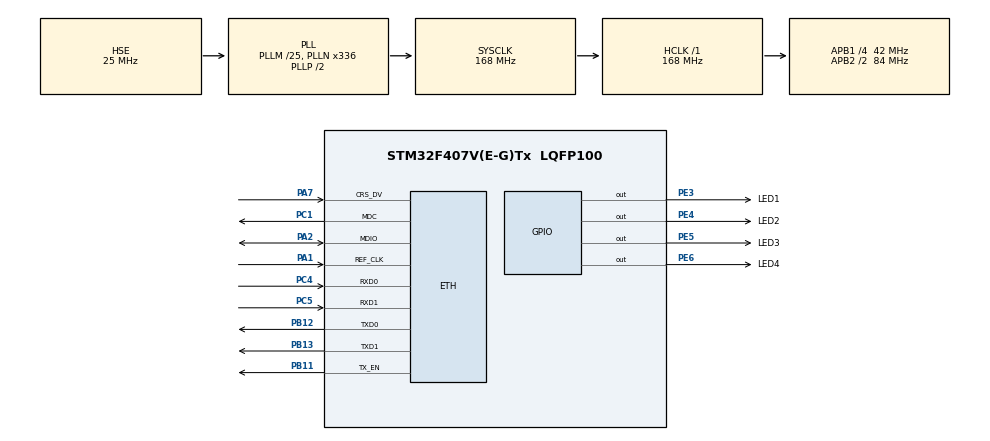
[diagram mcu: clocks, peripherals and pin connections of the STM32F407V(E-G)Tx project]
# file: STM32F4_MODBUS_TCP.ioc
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ETH.MediaInterface=ETH_MEDIA_INTERFACE_RMII
LWIP.GATEWAY_ADDRESS=017.091.001.002
LWIP.IP_ADDRESS=017.091.023.196
LWIP.LWIP_DHCP=0
LWIP.LWIP_UDP=1
LWIP.MEMP_NUM_TCP_PCB=3
LWIP.MEMP_NUM_UDP_PCB=3
LWIP.NETMASK_ADDRESS=255.255.224.000
LWIP.TCP_MSS=1460
LWIP.Version=v2.0.0_Cube
Mcu.Family=STM32F4
Mcu.Name=STM32F407V(E-G)Tx
Mcu.Package=LQFP100
NVIC.PriorityGroup=NVIC_PRIORITYGROUP_4
PA1.Mode=RMII
PA1.Signal=ETH_REF_CLK
PA13.Mode=JTAG_5_pins
PA13.Signal=SYS_JTMS-SWDIO
PA14.Mode=JTAG_5_pins
PA14.Signal=SYS_JTCK-SWCLK
PA15.Mode=JTAG_5_pins
PA15.Signal=SYS_JTDI
PA2.Mode=RMII
PA2.Signal=ETH_MDIO
PA7.Mode=RMII
PA7.Signal=ETH_CRS_DV
PB11.Mode=RMII
PB11.Signal=ETH_TX_EN
PB12.Mode=RMII
PB12.Signal=ETH_TXD0
PB13.Mode=RMII
PB13.Signal=ETH_TXD1
PB3.Mode=JTAG_5_pins
PB3.Signal=SYS_JTDO-SWO
PB4.Mode=JTAG_5_pins
PB4.Signal=SYS_JTRST
PC1.Mode=RMII
PC1.Signal=ETH_MDC
PC14-OSC32_IN.Mode=LSE-External-Oscillator
PC14-OSC32_IN.Signal=RCC_OSC32_IN
PC15-OSC32_OUT.Mode=LSE-External-Oscillator
PC15-OSC32_OUT.Signal=RCC_OSC32_OUT
PC4.Mode=RMII
PC4.Signal=ETH_RXD0
PC5.Mode=RMII
PC5.Signal=ETH_RXD1
PE3.GPIO_Label=LED1
PE3.Signal=GPIO_Output
PE4.GPIO_Label=LED2
PE4.Signal=GPIO_Output
PE5.GPIO_Label=LED3
PE5.Signal=GPIO_Output
PE6.GPIO_Label=LED4
PE6.Signal=GPIO_Output
PH0-OSC_IN.Mode=HSE-External-Oscillator
PH0-OSC_IN.Signal=RCC_OSC_IN
PH1-OSC_OUT.Mode=HSE-External-Oscillator
PH1-OSC_OUT.Signal=RCC_OSC_OUT
ProjectManager.HeapSize=0x200
ProjectManager.StackSize=0x400
ProjectManager.TargetToolchain=EWARM
RCC.48MHZClocksFreq_Value=84000000
RCC.AHBFreq_Value=168000000
RCC.APB1CLKDivider=RCC_HCLK_DIV4
RCC.APB1Freq_Value=42000000
RCC.APB1TimFreq_Value=84000000
RCC.APB2CLKDivider=RCC_HCLK_DIV2
RCC.APB2Freq_Value=84000000
RCC.APB2TimFreq_Value=168000000
RCC.CortexFreq_Value=168000000
RCC.HCLKFreq_Value=168000000
RCC.HSE_VALUE=25000000
RCC.HSI_VALUE=16000000
RCC.PLLM=25
RCC.PLLN=336
RCC.PLLSourceVirtual=RCC_PLLSOURCE_HSE
RCC.SYSCLKFreq_VALUE=168000000
RCC.SYSCLKSource=RCC_SYSCLKSOURCE_PLLCLK
RCC.VCOOutputFreq_Value=336000000
VP_LWIP_VS_Enabled.Mode=Enabled
VP_TIM7_VS_ClockSourceINT.Mode=Enable_Timer
board=STM32F4_MODBUS_TCP

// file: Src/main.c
/**
  ******************************************************************************
  * File Name          : main.c
  * Description        : Main program body
  ******************************************************************************
  * This notice applies to any and all portions of this file
  * that are not between comment pairs USER CODE BEGIN and
  * USER CODE END. Other portions of this file, whether
  * inserted by the user or by software development tools
  * are owned by their respective copyright owners.
  *
  * Copyright (c) 2017 STMicroelectronics International N.V.
  * All rights reserved.
  *
  * Redistribution and use in source and binary forms, with or without
  * modification, are permitted, provided that the following conditions are met:
  *
  * 1. Redistribution of source code must retain the above copyright notice,
  *    this list of conditions and the following disclaimer.
  * 2. Redistributions in binary form must reproduce the above copyright notice,
  *    this list of conditions and the following disclaimer in the documentation
  *    and/or other materials provided with the distribution.
  * 3. Neither the name of STMicroelectronics nor the names of other
  *    contributors to this software may be used to endorse or promote products
  *    derived from this software without specific written permission.
  * 4. This software, including modifications and/or derivative works of this
  *    software, must execute solely and exclusively on microcontroller or
  *    microprocessor devices manufactured by or for STMicroelectronics.
  * 5. Redistribution and use of this software other than as permitted under
  *    this license is void and will automatically terminate your rights under
  *    this license.
  *
  * THIS SOFTWARE IS PROVIDED BY STMICROELECTRONICS AND CONTRIBUTORS "AS IS"
  * AND ANY EXPRESS, IMPLIED OR STATUTORY WARRANTIES, INCLUDING, BUT NOT
  * LIMITED TO, THE IMPLIED WARRANTIES OF MERCHANTABILITY, FITNESS FOR A
  * PARTICULAR PURPOSE AND NON-INFRINGEMENT OF THIRD PARTY INTELLECTUAL PROPERTY
  * RIGHTS ARE DISCLAIMED TO THE FULLEST EXTENT PERMITTED BY LAW. IN NO EVENT
  * SHALL STMICROELECTRONICS OR CONTRIBUTORS BE LIABLE FOR ANY DIRECT, INDIRECT,
  * INCIDENTAL, SPECIAL, EXEMPLARY, OR CONSEQUENTIAL DAMAGES (INCLUDING, BUT NOT
  * LIMITED TO, PROCUREMENT OF SUBSTITUTE GOODS OR SERVICES; LOSS OF USE, DATA,
  * OR PROFITS; OR BUSINESS INTERRUPTION) HOWEVER CAUSED AND ON ANY THEORY OF
  * LIABILITY, WHETHER IN CONTRACT, STRICT LIABILITY, OR TORT (INCLUDING
  * NEGLIGENCE OR OTHERWISE) ARISING IN ANY WAY OUT OF THE USE OF THIS SOFTWARE,
  * EVEN IF ADVISED OF THE POSSIBILITY OF SUCH DAMAGE.
  *
  ******************************************************************************
  */
#include "main.h"
#include "stm32f4xx_hal.h"
#include "lwip.h"

/* USER CODE BEGIN Includes */
#include "mb.h"
#include "mbport.h"
/* USER CODE END Includes */

TIM_HandleTypeDef htim7;

/* USER CODE BEGIN PV */
/* Private variables ---------------------------------------------------------*/
extern struct netif gnetif;

/* USER CODE END PV */

void SystemClock_Config(void);
static void MX_GPIO_Init(void);
static void MX_TIM7_Init(void);

/* USER CODE BEGIN PFP */
/* Private function prototypes -----------------------------------------------*/
extern void ModbusTask();

/* USER CODE END PFP */

int main(void)
{

  /* MCU Configuration----------------------------------------------------------*/

  /* Reset of all peripherals, Initializes the Flash interface and the Systick. */
  HAL_Init();

  /* Configure the system clock */
  SystemClock_Config();

  /* Initialize all configured peripherals */
  MX_GPIO_Init();
  MX_TIM7_Init();
  MX_LWIP_Init();

  /* USER CODE BEGIN 2 */
  ModbusTask();

  /* USER CODE END 2 */

  /* Infinite loop */
  while (1)
  {

  }

}

/** System Clock Configuration
*/
void SystemClock_Config(void)
{

  RCC_OscInitTypeDef RCC_OscInitStruct;
  RCC_ClkInitTypeDef RCC_ClkInitStruct;

    /**Configure the main internal regulator output voltage
    */
  __HAL_RCC_PWR_CLK_ENABLE();

  __HAL_PWR_VOLTAGESCALING_CONFIG(PWR_REGULATOR_VOLTAGE_SCALE1);

    /**Initializes the CPU, AHB and APB busses clocks
    */
  RCC_OscInitStruct.OscillatorType = RCC_OSCILLATORTYPE_HSE;
  RCC_OscInitStruct.HSEState = RCC_HSE_ON;
  RCC_OscInitStruct.PLL.PLLState = RCC_PLL_ON;
  RCC_OscInitStruct.PLL.PLLSource = RCC_PLLSOURCE_HSE;
  RCC_OscInitStruct.PLL.PLLM = 25;
  RCC_OscInitStruct.PLL.PLLN = 336;
  RCC_OscInitStruct.PLL.PLLP = RCC_PLLP_DIV2;
  RCC_OscInitStruct.PLL.PLLQ = 4;
  if (HAL_RCC_OscConfig(&RCC_OscInitStruct) != HAL_OK)
  {
    _Error_Handler(__FILE__, __LINE__);
  }

    /**Initializes the CPU, AHB and APB busses clocks
    */
  RCC_ClkInitStruct.ClockType = RCC_CLOCKTYPE_HCLK|RCC_CLOCKTYPE_SYSCLK
                              |RCC_CLOCKTYPE_PCLK1|RCC_CLOCKTYPE_PCLK2;
  RCC_ClkInitStruct.SYSCLKSource = RCC_SYSCLKSOURCE_PLLCLK;
  RCC_ClkInitStruct.AHBCLKDivider = RCC_SYSCLK_DIV1;
  RCC_ClkInitStruct.APB1CLKDivider = RCC_HCLK_DIV4;
  RCC_ClkInitStruct.APB2CLKDivider = RCC_HCLK_DIV2;

  if (HAL_RCC_ClockConfig(&RCC_ClkInitStruct, FLASH_LATENCY_5) != HAL_OK)
  {
    _Error_Handler(__FILE__, __LINE__);
  }

    /**Configure the Systick interrupt time
    */
  HAL_SYSTICK_Config(HAL_RCC_GetHCLKFreq()/1000);

    /**Configure the Systick
    */
  HAL_SYSTICK_CLKSourceConfig(SYSTICK_CLKSOURCE_HCLK);

  /* SysTick_IRQn interrupt configuration */
  HAL_NVIC_SetPriority(SysTick_IRQn, 0, 0);
}

/* TIM7 init function */
static void MX_TIM7_Init(void)
{

  TIM_MasterConfigTypeDef sMasterConfig;

  htim7.Instance = TIM7;
  htim7.Init.Prescaler = 0;
  htim7.Init.CounterMode = TIM_COUNTERMODE_UP;
  htim7.Init.Period = 0;
  if (HAL_TIM_Base_Init(&htim7) != HAL_OK)
  {
    _Error_Handler(__FILE__, __LINE__);
  }

  sMasterConfig.MasterOutputTrigger = TIM_TRGO_RESET;
  sMasterConfig.MasterSlaveMode = TIM_MASTERSLAVEMODE_DISABLE;
  if (HAL_TIMEx_MasterConfigSynchronization(&htim7, &sMasterConfig) != HAL_OK)
  {
    _Error_Handler(__FILE__, __LINE__);
  }

}

/** Configure pins as
        * Analog
        * Input
        * Output
        * EVENT_OUT
        * EXTI
*/
static void MX_GPIO_Init(void)
{

  GPIO_InitTypeDef GPIO_InitStruct;

  /* GPIO Ports Clock Enable */
  __HAL_RCC_GPIOE_CLK_ENABLE();
  __HAL_RCC_GPIOC_CLK_ENABLE();
  __HAL_RCC_GPIOH_CLK_ENABLE();
  __HAL_RCC_GPIOA_CLK_ENABLE();
  __HAL_RCC_GPIOB_CLK_ENABLE();

  /*Configure GPIO pin Output Level */
  HAL_GPIO_WritePin(GPIOE, LED1_Pin|LED2_Pin|LED3_Pin|LED4_Pin, GPIO_PIN_RESET);

  /*Configure GPIO pins : LED1_Pin LED2_Pin LED3_Pin LED4_Pin */
  GPIO_InitStruct.Pin = LED1_Pin|LED2_Pin|LED3_Pin|LED4_Pin;
  GPIO_InitStruct.Mode = GPIO_MODE_OUTPUT_PP;
  GPIO_InitStruct.Pull = GPIO_NOPULL;
  GPIO_InitStruct.Speed = GPIO_SPEED_FREQ_LOW;
  HAL_GPIO_Init(GPIOE, &GPIO_InitStruct);

}

void _Error_Handler(char * file, int line)
{
  while(1)
  {
  }
}

/************************ (C) COPYRIGHT STMicroelectronics *****END OF FILE****/
